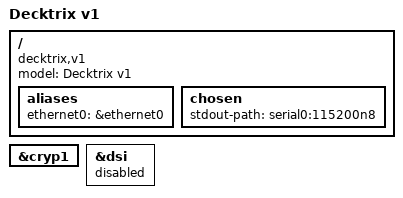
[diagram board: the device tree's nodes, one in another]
// SPDX-License-Identifier: (GPL-2.0+ OR BSD-3-Clause)
/*
 * Copyright (C) Decktrix Lab
 * Author: Kirill Yatsenko <kiriyatsenko@gmail.com>
 *
 * Decktrix v1 custom PCB based on STM32MP157F.
 * DSI disabled to avoid conflict with kernel Jadard driver.
 */

/dts-v1/;

#include "stm32mp157.dtsi"
#include "stm32mp15xc.dtsi"
#include "stm32mp15-pinctrl.dtsi"
#include "stm32mp15xxac-pinctrl.dtsi"
#include "stm32mp15xx-dkx.dtsi"

/ {
	model = "Decktrix v1";
	compatible = "decktrix,v1", "st,stm32mp157";

	aliases {
		ethernet0 = &ethernet0;
	};

	chosen {
		stdout-path = "serial0:115200n8";
	};
};

&cryp1 {
	status = "okay";
};

&dsi {
	status = "disabled";
};
